# nrf54h20_enga_radiocore register map
Vendor: Nordic Semiconductor; Series: nRF54h; File version: 1
CPU: CM33 r0p4, little endian, MPU, FPU, 3 interrupt priority bits, 480 interrupts, 4 SAU regions
Registers are 32-bit, read-write, reset 0x0 unless marked. A register's access mark holds for its fields unless they carry their own. Offsets are from the block's base; [hi:lo] are bit positions; lines under a group give offsets from that group; {n}, {i} and the like mark numbered series; 'fields as' and 'values as' point back to an identical list.

## CPUC_S — CM33 SubSystem
Base 0xE0080000
0x100 EVENTS_FPUIOC — An invalid operation exception has occurred in the FPU.
  [0] EVENTS_FPUIOC
    0=NotGenerated (Event not generated); 1=Generated (Event generated)
0x104 EVENTS_FPUDZC — A floating-point divide-by-zero exception has occurred in the FPU.
  [0] EVENTS_FPUDZC
    values as EVENTS_FPUIOC.EVENTS_FPUIOC
0x108 EVENTS_FPUOFC — A floating-point overflow exception has occurred in the FPU.
  [0] EVENTS_FPUOFC
    values as EVENTS_FPUIOC.EVENTS_FPUIOC
0x10C EVENTS_FPUUFC — A floating-point underflow exception has occurred in the FPU.
  [0] EVENTS_FPUUFC
    values as EVENTS_FPUIOC.EVENTS_FPUIOC
0x110 EVENTS_FPUIXC — A floating-point inexact exception has occurred in the FPU.
  [0] EVENTS_FPUIXC
    values as EVENTS_FPUIOC.EVENTS_FPUIOC
0x114 EVENTS_FPUIDC — A floating-point input denormal exception has occurred in the FPU.
  [0] EVENTS_FPUIDC
    values as EVENTS_FPUIOC.EVENTS_FPUIOC
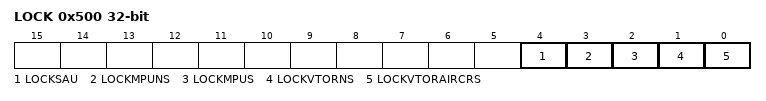
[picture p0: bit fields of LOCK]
0x500 LOCK — Register to lock the certain parts of the CPU from being modified.
  [4] LOCKSAU — Locks the Security Attribution Unit (SAU)
    0=NotLocked (SAU registers can be changed.); 1=Locked (Prevents changes to SAU registers.)
  [3] LOCKMPUNS — Locks the Memory Protection Unit (MPU) for non secure mode.
    0=NotLocked (MPU registers can be changed.); 1=Locked (Prevents changes to MPU registers.)
  [2] LOCKMPUS — Locks the Memory Protection Unit (MPU) for secure mode.
    values as LOCKMPUNS
  [1] LOCKVTORNS — Locks the Vector table Offset Register (VTOR) for non-secure mode.
    0=NotLocked (VTOR can be changed.); 1=Locked (Prevents changes to VTOR.)
  [0] LOCKVTORAIRCRS — Locks both the Vector table Offset Register (VTOR) and Application Interrupt and Reset Control Register (AIRCR) for secure mode.
    0=NotLocked (Both VTOR and AIRCR can be changed.); 1=Locked (Prevents changes to both VTOR and AIRCR.)
0x504 CPUID ro — The identifier for the CPU in this subsystem.
  [31:0] CPUID — The CPU identifier.

## RAMC000_NS — RAM Controller 0
Base 0x43004000
Same registers: RAMC001_NS 0x43038000, RAMC000_S 0x53004000, RAMC001_S 0x53038000
0x500 WAITSTATES — Waitstates for read operations.
  [0] WAITSTATES — Number of waitstates for a read from the RAM.
0x600 SECBASE — Base address for secure access area.
  [31:0] ADDR — Base address
0x604 SECENABLE — Enable secure access restrictions.
  [0] ENABLE — Enable secure access restrictions
    0=Disable (Secure access restrictions disabled); 1=Enable (Secure access restrictions enabled)

## PCGCS000_S — PCGCSlave 0
Base 0x5300C000
Same registers: PCGCS010_S 0x5301D000, PCGCS020_S 0x53021000, PCGCS030_S 0x5303E000
{0xC00+4i} PENALTY[{i}] (i=0..1) — Description collection: Penalty level for power/clock pair n
  [7:0] PENALTY — Penalty level
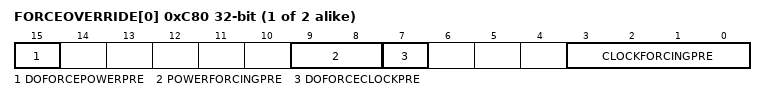
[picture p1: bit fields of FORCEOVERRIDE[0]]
{0xC80+4i} FORCEOVERRIDE[{i}] (i=0..1) — Description collection: Force override of power/clock pair n
  [15] DOFORCEPOWERPRE, [9:8] POWERFORCINGPRE, [7] DOFORCECLOCKPRE, [3:0] CLOCKFORCINGPRE

## LRCCONF000_S — LRCCONF 0
Base 0x5300E000
Same registers: LRCCONF010_S 0x5301E000, LRCCONF020_S 0x5302E000
{0x0+4i} TASKS_REQCLKSRC[{i}] (i=0..7) wo — Description collection: Request the clock source for clock [n]
  [0] TASKS_REQCLKSRC — Request the clock source for clock [n]
    1=Trigger task
{0x20+4i} TASKS_STOPREQCLKSRC[{i}] (i=0..7) wo — Description collection: Stop requesting the clock source for clock [n]
  [0] TASKS_STOPREQCLKSRC — Stop requesting the clock source for clock [n]
    1=Trigger task
0x40 TASKS_CONSTLAT group — Peripheral tasks.
  0x00 ENABLE wo — Enable constant latency mode
    [0] ENABLE
      1=Trigger task
  0x04 DISABLE wo — Disable constant latency mode
    [0] DISABLE
      1=Trigger task
0x48 TASKS_SYSTEMOFF group — Peripheral tasks.
  0x00 NOTREADY wo — Not ready to go to System OFF
    [0] NOTREADY
      1=Trigger task
  0x04 READY wo — Ready to go to System OFF
    [0] READY
      1=Trigger task
{0x100+4i} EVENTS_CLKSRCSTARTED[{i}] (i=0..7) — Description collection: Clock source is started for clock [n]
  [0] EVENTS_CLKSRCSTARTED — Clock source is started for clock [n]
    0=NotGenerated (Event not generated); 1=Generated (Event generated)
{0x400+8i} CLKSTAT[{i}] (i=0..7) group — Unspecified
  0x00 RUN — Description cluster: Status indicating that TASKS_REQCLKSRC task has been triggered for clock [n].
    [0] STATUS ro — Clock start task triggered or not
      0=NotTriggered (Task not triggered); 1=Triggered (Task triggered)
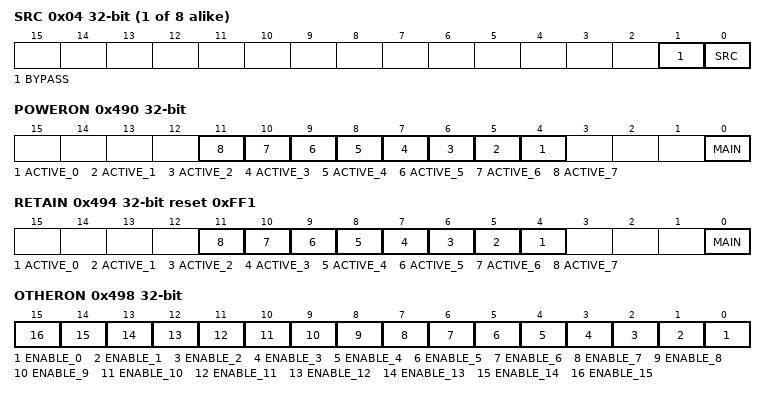
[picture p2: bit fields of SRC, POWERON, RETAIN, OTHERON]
  0x04 SRC — Description cluster: Status indicating clock source for clock [n]
    [1] BYPASS ro — Clock source bypass status
      0=Disable (Clock source bypass is disabled.); 1=Enable (Clock source bypass is enabled.)
    [0] SRC ro — Clock source status
      0=OpenLoop; 1=ClosedLoop
{0x440+8i} CLKCTRL[{i}] (i=0..7) group — Unspecified
  0x00 ALWAYSRUN — Description cluster: Force the clock [n] and tree running always
    [0] FORCE — Force the clock always running
      0=Automatic clock control enabled; 1=AlwaysRun (Clock always running)
  0x04 SRC — Description cluster: Select the clock source for clock [n]
    [1] BYPASS — Clock source bypass
      0=Disable the clock source bypass; 1=Enable the clock source bypass
    [0] SRC — Clock source
      0=OpenLoop; 1=ClosedLoop
0x480 CONSTLATSTAT ro — Status of constant latency
  [0] STATUS
    0=Disable (Constant latency disabled.); 1=Enable (Constant latency enabled.)
0x490 POWERON — Force power domain ON
  [all] fields
    0=Automatic power control enabled; 1=AlwaysOn (Keep the power domain ON even though there is no request)
  [n+4] ACTIVE_{n} (n=0..7) — Force the active power domain[{n}] ON
  [0] MAIN — Force the main power domain ON
0x494 RETAIN reset 0xFF1 — Retain power domain
  [all] fields
    0=Disable (Retain disabled); 1=Enable (Retain enabled)
  [n+4] ACTIVE_{n} (n=0..7) — Retain the active power domain[{n}]
  [0] MAIN ro — Retain the main power domain
0x498 OTHERON — Request other domain ON
  [all] fields
    0=Automatic power control enabled; 1=AlwaysOn (Request to keep the other power domain ON even though there is no request)
  [n] ENABLE_{n} (n=0..15) — Request power domain[{n}] ON
{0x500+4i} AX2XWAITSTATES[{i}] (i=0..15) reset 0x7 — Description collection: AX2X bridge waitstates for the domain [n], where n is the Domain ID.
  [2:0] WAITSTATES — Number of waitstates

## Notices in the file
Copyright (c) 2010 - 2024, Nordic Semiconductor ASA
All rights reserved.
Redistribution and use in source and binary forms, with or without modification,
are permitted provided that the following conditions are met:
1. Redistributions of source code must retain the above copyright notice, this
list of conditions and the following disclaimer.
2. Redistributions in binary form, except as embedded into a Nordic
Semiconductor ASA integrated circuit in a product or a software update for
such product, must reproduce the above copyright notice, this list of
conditions and the following disclaimer in the documentation and/or other
materials provided with the distribution.
3. Neither the name of Nordic Semiconductor ASA nor the names of its
contributors may be used to endorse or promote products derived from this
software without specific prior written permission.
4. This software, with or without modification, must only be used with a
Nordic Semiconductor ASA integrated circuit.
5. Any software provided in binary form under this license must not be reverse
engineered, decompiled, modified and/or disassembled.
THIS SOFTWARE IS PROVIDED BY NORDIC SEMICONDUCTOR ASA "AS IS" AND ANY EXPRESS
OR IMPLIED WARRANTIES, INCLUDING, BUT NOT LIMITED TO, THE IMPLIED WARRANTIES
OF MERCHANTABILITY, NONINFRINGEMENT, AND FITNESS FOR A PARTICULAR PURPOSE ARE
DISCLAIMED. IN NO EVENT SHALL NORDIC SEMICONDUCTOR ASA OR CONTRIBUTORS BE
LIABLE FOR ANY DIRECT, INDIRECT, INCIDENTAL, SPECIAL, EXEMPLARY, OR
CONSEQUENTIAL DAMAGES (INCLUDING, BUT NOT LIMITED TO, PROCUREMENT OF SUBSTITUTE
GOODS OR SERVICES; LOSS OF USE, DATA, OR PROFITS; OR BUSINESS INTERRUPTION)
HOWEVER CAUSED AND ON ANY THEORY OF LIABILITY, WHETHER IN CONTRACT, STRICT
LIABILITY, OR TORT (INCLUDING NEGLIGENCE OR OTHERWISE) ARISING IN ANY WAY OUT
OF THE USE OF THIS SOFTWARE, EVEN IF ADVISED OF THE POSSIBILITY OF SUCH DAMAGE.
